# RL6845_IP_SVD register map
Vendor: Realtek
Registers are 32-bit, read-write, reset 0x0 unless marked. A register's access mark holds for its fields unless they carry their own. Offsets are from the block's base; [hi:lo] are bit positions; lines under a group give offsets from that group; {n}, {i} and the like mark numbered series; 'fields as' and 'values as' point back to an identical list.

## PINMUX_REG
Base 0x41008800
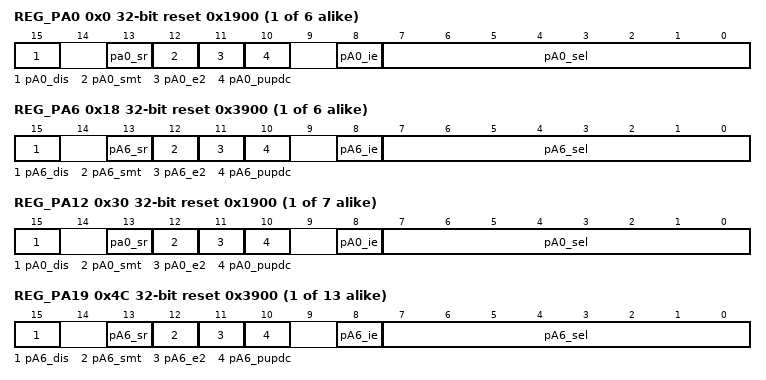
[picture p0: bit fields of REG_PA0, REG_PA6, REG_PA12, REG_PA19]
{0x0+4i} REG_PA{i} reset 0x1900 (i=0..5)
  [15] pA{i}_dis — PAD shutdown, only when the whole group's dis signals are all 1, the PAD SHDN will pull down to shutdown the group pad. 1. disable pad 0. enable pad
  [13] pa{i}_sr — PAD slew rate control
  [12] pA{i}_smt — PAD Schmit control
  [11] pA{i}_e2 — PAD driving ability control. 0: low 1: high The actual driving current is depend on pad type.
  [10] pA{i}_pupdc — Some pad may have two type of PU/PD resistor, this bit can select it. 1: small resistor 0: big resistor
  [8] pA{i}_ie — PAD input enable control
  [7:0] pA{i}_sel — PAD pinmux function ID selection
{0x0+4i} REG_PA{i} reset 0x3900 (i=6..11)
  [15] pA{i}_dis — PAD shutdown, only when the whole group's dis signals are all 1, the PAD SHDN will pull down to shutdown the group pad. 1. disable pad 0. enable pad
  [13] pA{i}_sr — PAD slew rate control. 1: slow 0: fast note: flash pad default 0 (PA0~5, PA12~18); other pads default 1
  [12] pA{i}_smt — PAD Schmit control
  [11] pA{i}_e2 — PAD driving ability control. 0: low 1: high The actual driving current is depend on pad type.
  [10] pA{i}_pupdc — Some pad may have two type of PU/PD resistor, this bit can select it. 1: small resistor 0: big resistor
  [8] pA{i}_ie — PAD input enable control
  [7:0] pA{i}_sel — PAD pinmux function ID selection
{0x0+4i} REG_PA{i} reset 0x1900 (i=12..18)
  fields as REG_PA0
{0x0+4i} REG_PA{i} reset 0x3900 (i=19..31)
  fields as REG_PA6
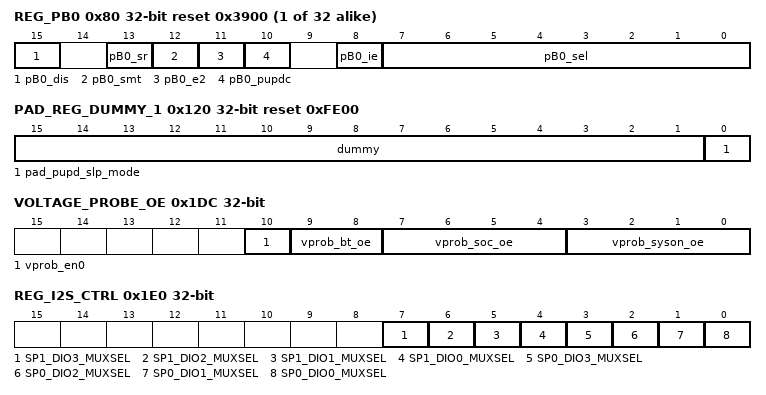
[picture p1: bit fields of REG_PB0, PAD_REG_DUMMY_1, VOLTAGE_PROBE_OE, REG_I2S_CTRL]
{0x80+4i} REG_PB{i} reset 0x3900 (i=0..31)
  [15] pB{i}_dis — PAD shutdown, only when the whole group's dis signals are all 1, the PAD SHDN will pull down to shutdown the group pad. 1. disable pad 0. enable pad
  [13] pB{i}_sr — PAD slew rate control. 1: slow 0: fast note: flash pad default 0 (PA0~5, PA12~18); other pads default 1
  [12] pB{i}_smt — PAD Schmit control
  [11] pB{i}_e2 — PAD driving ability control. 0: low 1: high The actual driving current is depend on pad type.
  [10] pB{i}_pupdc — Some pad may have two type of PU/PD resistor, this bit can select it. 1: small resistor 0: big resistor
  [8] pB{i}_ie — PAD input enable control
  [7:0] pB{i}_sel — PAD pinmux function ID selection
0x100 PAD_PU_1 reset 0x40022
  [31:0] pa_pu — PAD pull up enable when system is in active.
0x104 PAD_PU_2 reset 0xC0000020
  [31:0] pb_pu — PAD pull up enable when system is in active.
0x108 PAD_PD_1
  [31:0] pa_pd — PAD pull down enable when system is in active.
0x10C PAD_PD_2
  [31:0] pb_pd — PAD pull down enable when system is in active.
0x110 PAD_PU_SLP_1
  [31:0] pa_pu_slp — PAD pull up enable when system is in sleep.
0x114 PAD_PU_SLP_2
  [31:0] pb_pu_slp — PAD pull up enable when system is in sleep.
0x118 PAD_PD_SLP_1
  [31:0] pa_pd_slp — PAD pull down enable when system is in sleep.
0x11C PAD_PD_SLP_2
  [31:0] pb_pd_slp — PAD pull down enable when system is in sleep.
0x120 PAD_REG_DUMMY_1 reset 0xFE00
  [15:1] dummy — pad aon dummy bits
  [0] pad_pupd_slp_mode — pad pupd sleep mode seletion .
0x1DC VOLTAGE_PROBE_OE
  [10] vprob_en0 — pad vprob function enable
  [9:8] vprob_bt_oe — dummy bit, no use
  [7:4] vprob_soc_oe — dummy bit, no use
  [3:0] vprob_syson_oe — vprob source select, msut one-hot [0]: AON_OTP power [1]: SOC power [2]: BT power [3]: RSVD
0x1E0 REG_I2S_CTRL
  [7] SP1_DIO3_MUXSEL — SPORT1 DIO3 function mux 0: DIN_3 func 1: DOUT_0 func
  [6] SP1_DIO2_MUXSEL — SPORT1 DIO2 function mux 0: DIN_2 func 1: DOUT_1 func
  [5] SP1_DIO1_MUXSEL — SPORT1 DIO1 function mux 0: DIN_1 func 1: DOUT_2 func
  [4] SP1_DIO0_MUXSEL — SPORT1 DIO0 function mux 0: DIN_0 func 1: DOUT_3 func
  [3] SP0_DIO3_MUXSEL — SPORT0 DIO3 function mux 0: DIN_3 func 1: DOUT_0 func
  [2] SP0_DIO2_MUXSEL — SPORT0 DIO2 function mux 0: DIN_2 func 1: DOUT_1 func
  [1] SP0_DIO1_MUXSEL — SPORT0 DIO1 function mux 0: DIN_1 func 1: DOUT_2 func
  [0] SP0_DIO0_MUXSEL — SPORT0 DIO0 function mux 0: DIN_0 func 1: DOUT_3 func
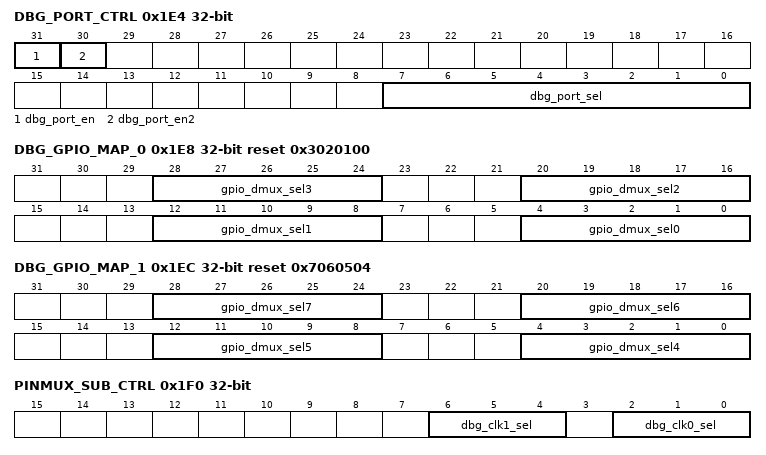
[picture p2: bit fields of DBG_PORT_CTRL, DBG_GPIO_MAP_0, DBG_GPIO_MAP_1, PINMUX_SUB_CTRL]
0x1E4 DBG_PORT_CTRL
  [31] dbg_port_en, [30] dbg_port_en2, [7:0] dbg_port_sel
0x1E8 DBG_GPIO_MAP_0 reset 0x3020100
  [8n+4:8n] gpio_dmux_sel{n} (n=0..3)
0x1EC DBG_GPIO_MAP_1 reset 0x7060504
  [8n-28:8n-32] gpio_dmux_sel{n} (n=4..7)
0x1F0 PINMUX_SUB_CTRL
  [6:4] dbg_clk1_sel — debug clock1 in CLOCK testmode 0: osc 1: osc100k 2: osc128k 3: xtal 4: sdm_32.768k 5: sdm_256Hz 6: sdm_1Hz 7: zero
  [2:0] dbg_clk0_sel — debug clock0 in CLOCK testmode 0: osc 1: osc100k 2: osc128k 3: xtal 4: sdm_32.768k 5: sdm_256Hz 6: sdm_1Hz 7: zero
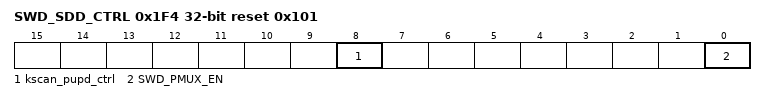
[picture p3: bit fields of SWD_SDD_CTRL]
0x1F4 SWD_SDD_CTRL reset 0x101
  [8] kscan_pupd_ctrl — enable kscan pupd hw control logic, active 1
  [0] SWD_PMUX_EN — 1: Force enable share SWD pinmux function 0: Disable
0x1FC PAD_REG_DUMMY_0 reset 0xFFFF
  [31:0] dummy — HW used only , these are for reserved.
